AUTOSAR XML (schema 4-2-1)
package /ComponentTypes
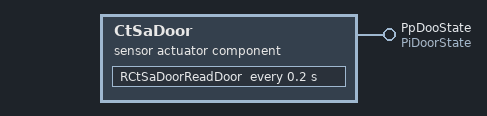
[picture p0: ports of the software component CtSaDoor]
  sensor actuator sw component type CtSaDoor
    provide port PpDooState: nonqueued-sender-com-spec{data-element=DeDoorState, init-value=constant-reference=CDoorClosed}, provided-interface=PiDoorState
    behavior CtSaDoor_InternalBehavior: data-type-mapping=DemoTypeMapping, supports-multiple-instantiation=true
      timing event TMT_RCtSaDoorReadDoor: start-on-event=RCtSaDoorReadDoor, period=0.2
      runnable RCtSaDoorReadDoor
        data-send-points:
          access SEND_PpDooState_DeDoorState: accessed-variable=PpDooState.DeDoorState
  swc implementation CtSaDoor_Implementation: behavior=CtSaDoor_InternalBehavior
    code-descriptors:
      code Default: artifact-descriptors=autosar-engineering-object={short-label=Default, category=SWSRC}
